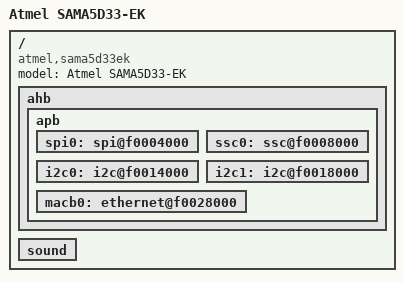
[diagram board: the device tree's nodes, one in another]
/*
 * sama5d33ek.dts - Device Tree file for SAMA5D33-EK board
 *
 *  Copyright (C) 2013 Atmel,
 *                2013 Ludovic Desroches <ludovic.desroches@atmel.com>
 *
 * Licensed under GPLv2 or later.
 */
/dts-v1/;
#include "sama5d33.dtsi"
#include "sama5d3xmb.dtsi"
#include "sama5d3xmb_gmac.dtsi"
#include "sama5d3xdm.dtsi"

/ {
	model = "Atmel SAMA5D33-EK";
	compatible = "atmel,sama5d33ek", "atmel,sama5d3xmb", "atmel,sama5d3xcm", "atmel,sama5d33", "atmel,sama5d3", "atmel,sama5";

	ahb {
		apb {
			spi0: spi@f0004000 {
				status = "okay";
			};

			ssc0: ssc@f0008000 {
				status = "okay";
			};

			i2c0: i2c@f0014000 {
				status = "okay";
			};

			i2c1: i2c@f0018000 {
				status = "okay";
			};

			macb0: ethernet@f0028000 {
				status = "okay";
			};
		};
	};

	sound {
		status = "okay";
	};
};
